# nrf54ls05b_enga_application register map
Vendor: Nordic Semiconductor; Series: nrf54l; File version: 1
CPU: CM33 r0p4, little endian, no MPU, no FPU, 3 interrupt priority bits, 270 interrupts
Registers are 32-bit, read-write, reset 0x0 unless marked. A register's access mark holds for its fields unless they carry their own. Offsets are from the block's base; [hi:lo] are bit positions; lines under a group give offsets from that group; {n}, {i} and the like mark numbered series; 'fields as' and 'values as' point back to an identical list.

## CPUC — CPU control
Base 0xE0080000
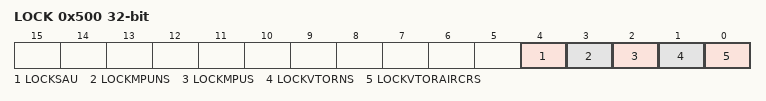
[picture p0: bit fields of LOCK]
0x500 LOCK — Register to lock the certain parts of the CPU from being modified.
  [4] LOCKSAU — Locks the Security Attribution Unit (SAU)
    0=NotLocked (SAU registers can be changed.); 1=Locked (Prevents changes to SAU registers.)
  [3] LOCKMPUNS — Locks the Memory Protection Unit (MPU) for non secure mode.
    0=NotLocked (MPU registers can be changed.); 1=Locked (Prevents changes to MPU registers.)
  [2] LOCKMPUS — Locks the Memory Protection Unit (MPU) for secure mode.
    values as LOCKMPUNS
  [1] LOCKVTORNS — Locks the Vector table Offset Register (VTOR) for non-secure mode.
    0=NotLocked (VTOR can be changed.); 1=Locked (Prevents changes to VTOR.)
  [0] LOCKVTORAIRCRS — Locks both the Vector table Offset Register (VTOR) and Application Interrupt and Reset Control Register (AIRCR) for secure mode.
    0=NotLocked (Both VTOR and AIRCR can be changed.); 1=Locked (Prevents changes to both VTOR and AIRCR.)
0x504 CPUID ro — The identifier for the CPU in this subsystem.
  [31:0] CPUID — The CPU identifier.

## ICACHE — Cache
Base 0xE0082000
0x08 TASKS_INVALIDATECACHE wo — Invalidate the cache.
  [0] TASKS_INVALIDATECACHE
    1=Trigger task
0x400 STATUS ro — Status of the cache activities.
  [0] READY — Ready status.
    0=Ready (Activity is done and ready for the next activity.); 1=Busy (Activity is in progress.)
0x404 ENABLE — Enable cache.
  [0] ENABLE — Enable cache
    0=Disabled (Disable cache); 1=Enabled (Enable cache)
0x414 PROFILING group — Unspecified
  0x00 ENABLE — Enable the profiling counters.
    [0] ENABLE — Enable the profiling counters
      0=Disable profiling; 1=Enable profiling
  0x04 CLEAR wo — Clear the profiling counters.
    [0] CLEAR — Clearing the profiling counters
      1=Clear the profiling counters
  0x08 HIT ro — The cache hit counter for cache region.
    [31:0] HITS — Number of cache hits
  0x0C MISS ro — The cache miss counter for cache region.
    [31:0] MISSES — Number of cache misses

## SWI00 — Software interrupt 0
Base 0x4001C000
Same registers: SWI01 0x4001D000, SWI02 0x4001E000, SWI03 0x4001F000

## GLOBAL_DPPIC00 — Distributed programmable peripheral interconnect controller 0
Base 0x40042000
Same registers: GLOBAL_DPPIC10 0x40082000, GLOBAL_DPPIC20 0x400C2000, GLOBAL_DPPIC30 0x40102000
{0x0+8i} TASKS_CHG[{i}] (i=0..5) group — Channel group tasks
  0x00 EN wo — Description cluster: Enable channel group n
    [0] EN — Enable channel group n
      1=Trigger task
  0x04 DIS wo — Description cluster: Disable channel group n
    [0] DIS — Disable channel group n
      1=Trigger task
{0x80+8i} SUBSCRIBE_CHG[{i}] (i=0..5) group — Subscribe configuration for tasks
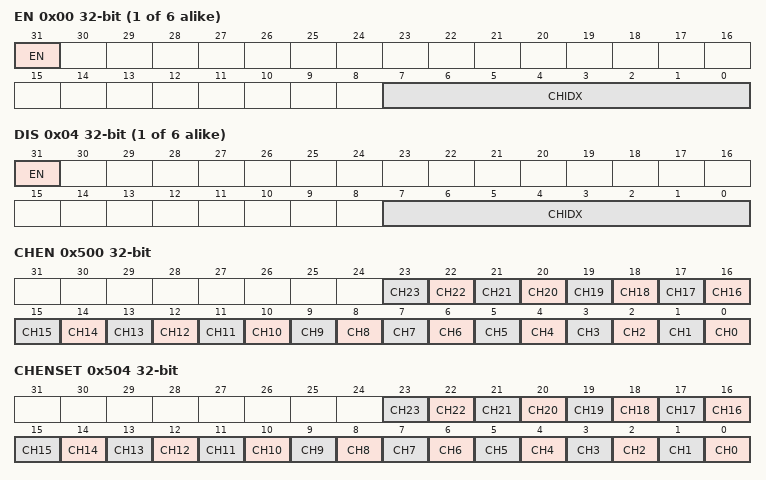
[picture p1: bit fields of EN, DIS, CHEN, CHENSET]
  0x00 EN — Description cluster: Subscribe configuration for task CHG[n].EN
    [31] EN
      0=Disabled (Disable subscription); 1=Enabled (Enable subscription)
    [7:0] CHIDX — DPPI channel that task CHG[n].EN will subscribe to
  0x04 DIS — Description cluster: Subscribe configuration for task CHG[n].DIS
    [31] EN
      values as SUBSCRIBE_CHG[0].EN.EN
    [7:0] CHIDX — DPPI channel that task CHG[n].DIS will subscribe to
0x500 CHEN — Channel enable register
  [all] fields
    0=Disabled (Disable channel); 1=Enabled (Enable channel)
  [n] CH{n} (n=0..23) — Enable or disable channel {n}
0x504 CHENSET write-1-sets — Channel enable set register
  [all] fields
    on read: 0=Disabled (Read: Channel disabled); 1=Enabled (Read: Channel enabled) | on write: 1=Set (Write: Enable channel)
  [n] CH{n} (n=0..23) — Channel {n} enable set register. Writing 0 has no effect.
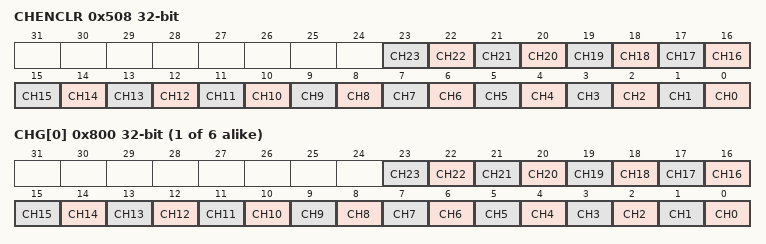
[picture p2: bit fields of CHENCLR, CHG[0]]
0x508 CHENCLR write-1-clears — Channel enable clear register
  [all] fields
    on read: 0=Disabled (Read: Channel disabled); 1=Enabled (Read: Channel enabled) | on write: 1=Clear (Write: Disable channel)
  [n] CH{n} (n=0..23) — Channel {n} enable clear register. Writing 0 has no effect.
{0x800+4i} CHG[{i}] (i=0..5) — Description collection: Channel group n Note: Writes to this register are ignored if either SUBSCRIBE_CHG[n].EN or SUBSCRIBE_CHG[n].DIS is enabled
  [all] fields
    0=Excluded; 1=Included
  [n] CH{n} (n=0..23) — Include or exclude channel {n}
